VERSION "0.0.02"

NS_ :

BS_:

BO_ 928 EPB_STATUS: 8 XXX
 SG_ EPB_BRAKE : 16|1@1+ (1,0) [0|3] "" XXX

BO_ 1104 SEATBELT_STATUS: 8 XXX
 SG_ DRIVER_SEAT_BELT_ONOFF : 21|1@0+ (1,0) [0|3] "" XXX

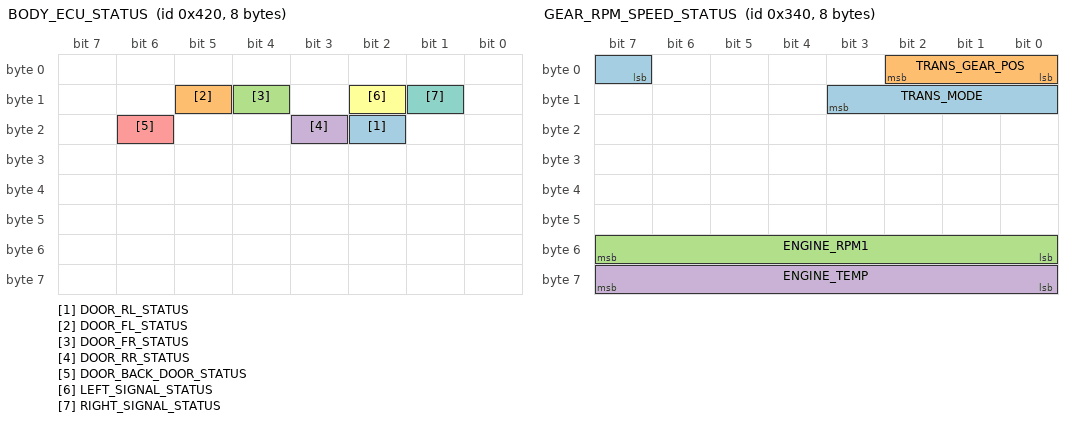
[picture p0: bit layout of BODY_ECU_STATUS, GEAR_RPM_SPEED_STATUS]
BO_ 1056 BODY_ECU_STATUS: 8 XXX
 SG_ DOOR_RL_STATUS : 18|1@0+ (1,0) [0|255] "" XXX
 SG_ DOOR_FL_STATUS : 13|1@0+ (1,0) [0|1] "" XXX
 SG_ DOOR_FR_STATUS : 12|1@0+ (1,0) [0|1] "" XXX
 SG_ DOOR_RR_STATUS : 19|1@0+ (1,0) [0|1] "" XXX
 SG_ DOOR_BACK_DOOR_STATUS : 22|1@0+ (1,0) [0|1] "" XXX
 SG_ LEFT_SIGNAL_STATUS : 10|1@0+ (1,0) [0|1] "" XXX
 SG_ RIGHT_SIGNAL_STATUS : 9|1@0+ (1,0) [0|1] "" XXX

BO_ 832 GEAR_RPM_SPEED_STATUS: 8 XXX
 SG_ TRANS_MODE : 7|5@1+ (1,0) [0|0] "" XXX
 SG_ TRANS_GEAR_POS : 2|3@0+ (1,0) [0|1] "" XXX
 SG_ ENGINE_RPM1 : 55|8@0+ (1,0) [0|255] "" XXX
 SG_ ENGINE_TEMP : 63|8@0+ (1,0) [0|255] "" XXX

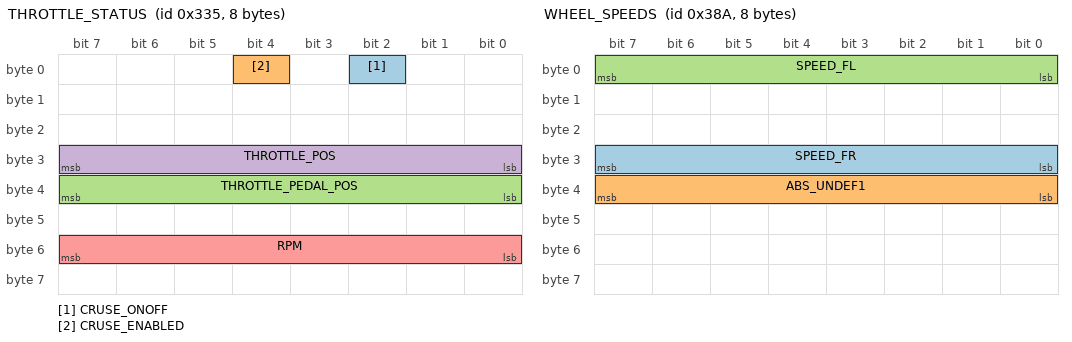
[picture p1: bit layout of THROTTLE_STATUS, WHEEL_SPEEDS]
BO_ 821 THROTTLE_STATUS: 8 XXX
 SG_ CRUSE_ONOFF : 2|1@0+ (1,0) [0|1] "on/off" XXX
 SG_ CRUSE_ENABLED : 4|1@0+ (1,0) [0|1] "" XXX
 SG_ THROTTLE_PEDAL_POS : 32|8@1+ (1,0) [0|255] "" XXX
 SG_ THROTTLE_POS : 24|8@1+ (1,0) [0|255] "" XXX
 SG_ RPM : 48|8@1- (1,0) [0|65535] "" XXX

BO_ 922 STEERING_ANGLE_STATUS: 8 XXX
 SG_ STEER_ANGLE_9000 : 7|16@0- (1,0) [0|65535] "" XXX

BO_ 906 WHEEL_SPEEDS: 8 XXX
 SG_ SPEED_FR : 24|8@1+ (1,0) [0|255] "" XXX
 SG_ ABS_UNDEF1 : 32|8@1+ (1,0) [0|255] "" XXX
 SG_ SPEED_FL : 0|8@1+ (1,0) [0|255] "" XXX

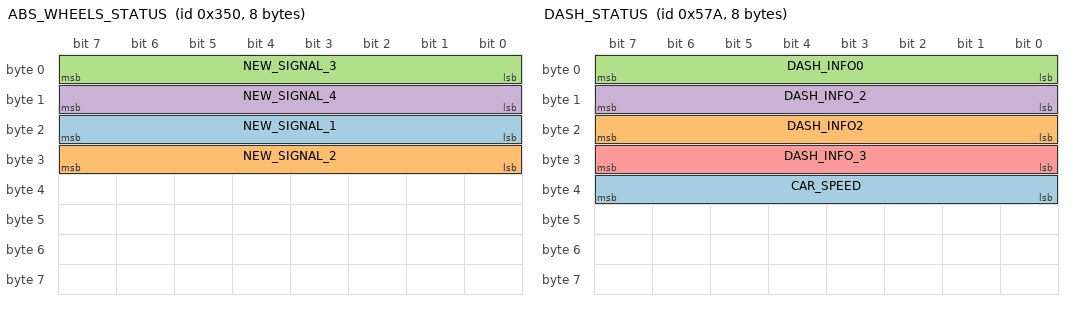
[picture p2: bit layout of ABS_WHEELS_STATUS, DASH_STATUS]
BO_ 848 ABS_WHEELS_STATUS: 8 XXX
 SG_ NEW_SIGNAL_1 : 23|8@0+ (1,0) [0|255] "" XXX
 SG_ NEW_SIGNAL_2 : 31|8@0+ (1,0) [0|255] "" XXX
 SG_ NEW_SIGNAL_3 : 7|8@0+ (1,0) [0|255] "" XXX
 SG_ NEW_SIGNAL_4 : 15|8@0+ (1,0) [0|255] "" XXX

BO_ 1402 DASH_STATUS: 8 XXX
 SG_ CAR_SPEED : 32|8@1+ (1,0) [0|255] "" XXX
 SG_ DASH_INFO2 : 16|8@1+ (1,0) [0|255] "" XXX
 SG_ DASH_INFO0 : 0|8@1+ (1,0) [0|255] "" XXX
 SG_ DASH_INFO_2 : 15|8@0+ (1,0) [0|255] "" XXX
 SG_ DASH_INFO_3 : 31|8@0+ (1,0) [0|255] "" XXX

BO_ 1306 _SPEEDX: 8 XXX
 SG_ DASH_CAR_SPEED : 7|9@0+ (1,0) [0|255] "" XXX

BO_ 1296 undefined: 8 XXX

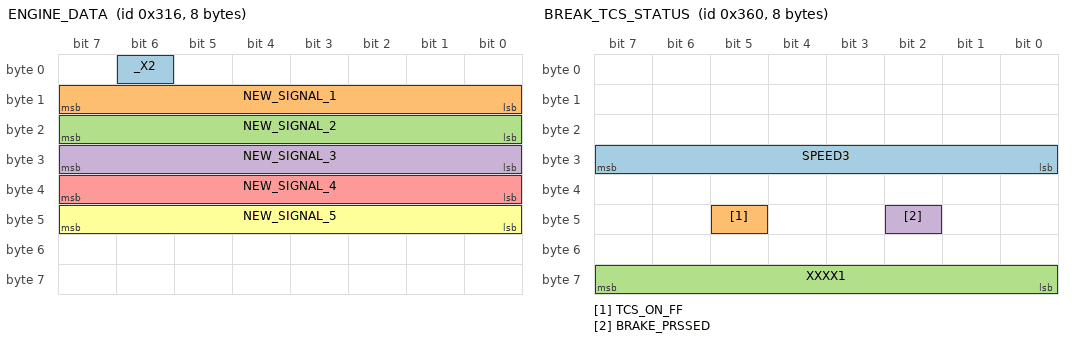
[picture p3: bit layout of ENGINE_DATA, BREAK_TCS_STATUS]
BO_ 790 ENGINE_DATA: 8 XXX
 SG_ _X2 : 6|1@0+ (1,0) [0|1] "" XXX
 SG_ NEW_SIGNAL_1 : 15|8@0+ (1,0) [0|255] "" XXX
 SG_ NEW_SIGNAL_2 : 23|8@0+ (1,0) [0|255] "" XXX
 SG_ NEW_SIGNAL_3 : 31|8@0+ (1,0) [0|255] "" XXX
 SG_ NEW_SIGNAL_4 : 39|8@0+ (1,0) [0|255] "" XXX
 SG_ NEW_SIGNAL_5 : 47|8@0+ (1,0) [0|255] "" XXX

BO_ 1313 undefined_2: 8 XXX

BO_ 1312 __trigger_every_range: 8 XXX
 SG_ __SIGNAL_every_interval : 4|1@0+ (1,0) [0|1] "" XXX

BO_ 896 undefined_3: 8 XXX
 SG_ NEW_SIGNAL_1 : 32|4@1+ (1,0) [0|15] "" XXX

BO_ 809 undefined_4: 8 XXX

BO_ 864 BREAK_TCS_STATUS: 8 XXX
 SG_ SPEED3 : 24|8@1+ (1,0) [0|255] "" XXX
 SG_ TCS_ON_FF : 45|1@0+ (1,0) [0|1] "" XXX
 SG_ XXXX1 : 63|8@0+ (1,0) [0|255] "" XXX
 SG_ BRAKE_PRSSED : 42|1@0+ (1,0) [0|1] "" XXX

BO_ 842 undefined_5: 8 XXX

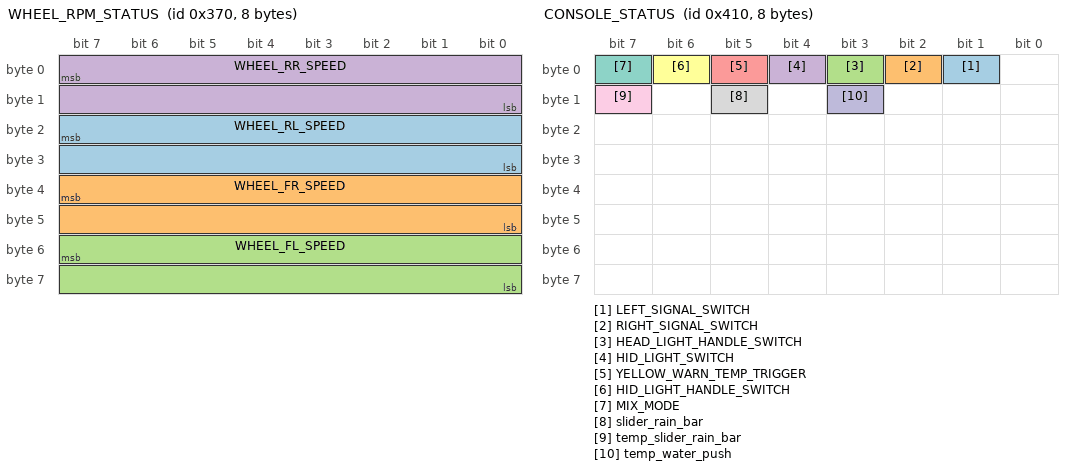
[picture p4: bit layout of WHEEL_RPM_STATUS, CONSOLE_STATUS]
BO_ 880 WHEEL_RPM_STATUS: 8 XXX
 SG_ WHEEL_RL_SPEED : 23|16@0+ (1,0) [0|255] "" XXX
 SG_ WHEEL_FR_SPEED : 39|16@0+ (1,0) [0|255] "" XXX
 SG_ WHEEL_FL_SPEED : 55|16@0+ (1,0) [0|255] "" XXX
 SG_ WHEEL_RR_SPEED : 7|16@0- (1,0) [0|255] "" XXX

BO_ 1040 CONSOLE_STATUS: 8 XXX
 SG_ LEFT_SIGNAL_SWITCH : 1|1@0+ (1,0) [0|1] "" XXX
 SG_ RIGHT_SIGNAL_SWITCH : 2|1@0+ (1,0) [0|1] "" XXX
 SG_ HEAD_LIGHT_HANDLE_SWITCH : 3|1@0+ (1,0) [0|1] "" XXX
 SG_ HID_LIGHT_SWITCH : 4|1@0+ (1,0) [0|1] "" XXX
 SG_ YELLOW_WARN_TEMP_TRIGGER : 5|1@0+ (1,0) [0|1] "" XXX
 SG_ HID_LIGHT_HANDLE_SWITCH : 6|1@0+ (1,0) [0|1] "" XXX
 SG_ MIX_MODE : 7|1@0+ (1,0) [0|1] "" XXX
 SG_ slider_rain_bar : 13|1@0+ (1,0) [0|1] "" XXX
 SG_ temp_slider_rain_bar : 15|1@0+ (1,0) [0|1] "" XXX
 SG_ temp_water_push : 11|1@0+ (1,0) [0|1] "" XXX

BO_ 1120 HAVC_STATUS: 8 XXX
 SG_ HAVC_TEMP : 32|8@1+ (1,0) [0|255] "" XXX

BU_: XXX

CM_ BU_ K182_PACM "Parking Assist Control Module";
CM_ BU_ K43_PSCM "Power Steering Control Module";
CM_ BU_ K17_EBCM "Electronic Brake Control Module";
CM_ BU_ NEO "Comma NEO";
CM_ BU_ K124_ASCM "Active Safety Control Module";
BA_DEF_  "UseGMParameterIDs" INT 0 0;
BA_DEF_  "ProtocolType" STRING ;
BA_DEF_  "BusType" STRING ;
BA_DEF_DEF_  "UseGMParameterIDs" 1;
BA_DEF_DEF_  "ProtocolType" "GMLAN";
BA_DEF_DEF_  "BusType" "";
BA_ "UseGMParameterIDs" 0;
BA_ "BusType" "CAN";

VAL_ 262 DI_torqueDriver -4096 "SNA" ;
VAL_ 262 DI_torqueMotor -4096 "SNA" ;
VAL_ 262 DI_soptState 7 "SOPT_TEST_SNA" 4 "SOPT_TEST_NOT_RUN" 3 "SOPT_TEST_PASSED" 2 "SOPT_TEST_FAILED" 1 "SOPT_TEST_IN_PROGRESS" 0 "SOPT_PRE_TEST" ;
VAL_ 262 DI_motorRPM -32768 "SNA" ;
VAL_ 262 DI_pedalPos 255 "SNA" ;
VAL_ 278 DI_torqueEstimate -2048 "SNA" ;
VAL_ 278 DI_gear 7 "DI_GEAR_SNA" 4 "DI_GEAR_D" 3 "DI_GEAR_N" 2 "DI_GEAR_R" 1 "DI_GEAR_P" 0 "DI_GEAR_INVALID" ;
VAL_ 278 DI_brakePedal 1 "Applied" 0 "Not_applied" ;
VAL_ 278 DI_vehicleSpeed 4095 "SNA" ;
VAL_ 278 DI_gearRequest 7 "DI_GEAR_SNA" 4 "DI_GEAR_D" 3 "DI_GEAR_N" 2 "DI_GEAR_R" 1 "DI_GEAR_P" 0 "DI_GEAR_INVALID" ;
VAL_ 278 DI_torqueInterfaceFailure 1 "TORQUE_INTERFACE_FAILED" 0 "TORQUE_INTERFACE_NORMAL" ;
VAL_ 278 DI_brakePedalState 3 "SNA" 2 "INVALID" 1 "ON" 0 "OFF" ;
VAL_ 278 DI_epbParkRequest 1 "Park_requested" 0 "No_request" ;
VAL_ 278 DI_epbInterfaceReady 1 "EPB_INTERFACE_READY" 0 "EPB_INTERFACE_NOT_READY" ;
VAL_ 504 driverBrakeStatus 2 "APPLIED" 1 "NOT_APPLIED" ;
VAL_ 568 SpdCtrlLvr_Stat 32 "DN_1ST" 16 "UP_1ST" 8 "DN_2ND" 4 "UP_2ND" 2 "RWD" 1 "FWD" 0 "IDLE" ;
VAL_ 568 DTR_Dist_Rq 255 "SNA" 200 "ACC_DIST_7" 166 "ACC_DIST_6" 133 "ACC_DIST_5" 100 "ACC_DIST_4" 66 "ACC_DIST_3" 33 "ACC_DIST_2" 0 "ACC_DIST_1" ;
VAL_ 568 TurnIndLvr_Stat 3 "SNA" 2 "RIGHT" 1 "LEFT" 0 "IDLE" ;
VAL_ 568 HiBmLvr_Stat 3 "SNA" 2 "HIBM_FLSH_ON_PSD" 1 "HIBM_ON_PSD" 0 "IDLE" ;
VAL_ 568 WprWashSw_Psd 3 "SNA" 2 "WASH" 1 "TIPWIPE" 0 "NPSD" ;
VAL_ 568 WprWash_R_Sw_Posn_V2 3 "SNA" 2 "WASH" 1 "INTERVAL" 0 "OFF" ;
VAL_ 568 StW_Lvr_Stat 4 "STW_BACK" 3 "STW_FWD" 2 "STW_DOWN" 1 "STW_UP" 0 "NPSD" ;
VAL_ 568 StW_Cond_Psd 3 "SNA" 2 "DOWN" 1 "UP" 0 "NPSD" ;
VAL_ 568 HrnSw_Psd 3 "SNA" 2 "NDEF2" 1 "PSD" 0 "NPSD" ;
VAL_ 568 StW_Sw00_Psd 1 "PRESSED" 0 "NOT_PRESSED_SNA" ;
VAL_ 568 StW_Sw01_Psd 1 "PRESSED" 0 "NOT_PRESSED_SNA" ;
VAL_ 568 StW_Sw03_Psd 1 "PRESSED" 0 "NOT_PRESSED_SNA" ;
VAL_ 568 StW_Sw04_Psd 1 "PRESSED" 0 "NOT_PRESSED_SNA" ;
VAL_ 568 WprSw6Posn 7 "SNA" 6 "STAGE2" 5 "STAGE1" 4 "INTERVAL4" 3 "INTERVAL3" 2 "INTERVAL2" 1 "INTERVAL1" 0 "OFF" ;
VAL_ 598 DI_aebState 2 "ENABLED" 4 "FAULT" 7 "SNA" 1 "STANDBY" 3 "STANDSTILL" 0 "UNAVAILABLE" ;
VAL_ 598 DI_analogSpeed 4095 "SNA" ;
VAL_ 598 DI_cruiseState 2 "ENABLED" 5 "FAULT" 0 "OFF" 4 "OVERRIDE" 7 "PRE_CANCEL" 6 "PRE_FAULT" 1 "STANDBY" 3 "STANDSTILL" ;
VAL_ 598 DI_digitalSpeed 255 "SNA" ;
VAL_ 598 DI_immobilizerState 2 "AUTHENTICATING" 3 "DISARMED" 6 "FAULT" 4 "IDLE" 0 "INIT_SNA" 1 "REQUEST" 5 "RESET" ;
VAL_ 598 DI_speedUnits 1 "KPH" 0 "MPH" ;
VAL_ 598 DI_state 3 "ABORT" 4 "ENABLE" 2 "FAULT" 1 "STANDBY" 0 "UNAVAILABLE" ;
VAL_ 598 DI_systemState 3 "ABORT" 4 "ENABLE" 2 "FAULT" 1 "STANDBY" 0 "UNAVAILABLE" ;
VAL_ 598 DI_vehicleHoldState 2 "BLEND_IN" 4 "BLEND_OUT" 6 "FAULT" 7 "INIT" 5 "PARK" 1 "STANDBY" 3 "STANDSTILL" 0 "UNAVAILABLE" ;
VAL_ 703 DAS_setSpeed 4095 "SNA" ;
VAL_ 703 DAS_accState 15 "FAULT_SNA" 13 "ACC_CANCEL_GENERIC_SILENT" 11 "APC_SELFPARK_START" 10 "APC_UNPARK_COMPLETE" 9 "APC_PAUSE" 8 "APC_ABORT" 7 "APC_COMPLETE" 6 "APC_FORWARD" 5 "APC_BACKWARD" 4 "ACC_ON" 3 "ACC_HOLD" 0 "ACC_CANCEL_GENERIC" ;
VAL_ 703 DAS_aebEvent 3 "AEB_SNA" 2 "AEB_FAULT" 1 "AEB_ACTIVE" 0 "AEB_NOT_ACTIVE" ;
VAL_ 703 DAS_jerkMin 511 "SNA" ;
VAL_ 703 DAS_jerkMax 255 "SNA" ;
VAL_ 703 DAS_accelMin 511 "SNA" ;
